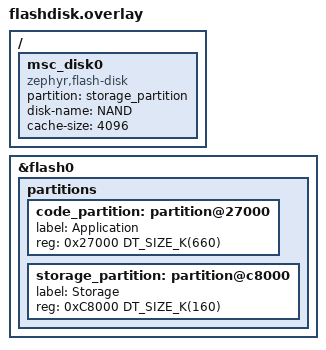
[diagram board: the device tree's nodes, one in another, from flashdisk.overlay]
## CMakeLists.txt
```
# SPDX-License-Identifier: Apache-2.0

cmake_minimum_required(VERSION 3.20.0)
find_package(Zephyr REQUIRED HINTS $ENV{ZEPHYR_BASE})
project(lsm6dsl)

FILE(GLOB app_sources src/*.c)
target_sources(app PRIVATE ${app_sources})

set(MOTION_DIR ${CMAKE_CURRENT_SOURCE_DIR}/../../../examples/motion_recognition/)
set(MOTION_MODEL_IN ${CMAKE_CURRENT_SOURCE_DIR}/combined.estimator.pickle)
set(MOTION_MODEL_OUT ${CMAKE_CURRENT_BINARY_DIR}/motion_model.h)

set(GRAVITY_FILTER_OUT ${CMAKE_CURRENT_BINARY_DIR}/motion_gravity_lowpass.h)

# Custom command for motion_model.h
add_custom_command(
  OUTPUT ${MOTION_MODEL_OUT}
  COMMAND ${CMAKE_COMMAND} -E make_directory ${CMAKE_CURRENT_BINARY_DIR}
  COMMAND python3 ${MOTION_DIR}/tools/convert_model.py --out ${MOTION_MODEL_OUT} --model ${MOTION_MODEL_IN}
  DEPENDS ${MOTION_DIR}/tools/convert_model.py
  COMMENT "Generating motion_model.h"
  WORKING_DIRECTORY ${CMAKE_CURRENT_SOURCE_DIR}
)
add_custom_target(generate_model ALL
  DEPENDS ${MOTION_MODEL_IN} ${MOTION_MODEL_OUT}
)

# Custom command for gravity filter
add_custom_command(
  OUTPUT ${GRAVITY_FILTER_OUT}
  COMMAND ${CMAKE_COMMAND} -E make_directory ${CMAKE_CURRENT_BINARY_DIR}
  COMMAND python3 ${MOTION_DIR}/tools/gravity_lowpass.py --out ${GRAVITY_FILTER_OUT} --format header
  DEPENDS ${MOTION_DIR}/tools/gravity_lowpass.py
  COMMENT "Generating gravity_lowpass.h"
  WORKING_DIRECTORY ${CMAKE_CURRENT_SOURCE_DIR}
)
add_custom_target(generate_filter ALL
  DEPENDS ${GRAVITY_FILTER_OUT}
)

target_include_directories(app PRIVATE 
    ${MOTION_DIR}
    ${CMAKE_CURRENT_BINARY_DIR}
    ${ZEPHYR_BASE}/samples/subsys/usb/common
)

add_dependencies(app generate_model generate_filter)

target_sources(app PRIVATE
    # ${ZEPHYR_BASE}/samples/subsys/usb/common/sample_usbd_init.c
)
```

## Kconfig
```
# Copyright (c) 2019-2020 Nordic Semiconductor ASA
# SPDX-License-Identifier: Apache-2.0

menu "MSC sample options"

config APP_WIPE_STORAGE
	bool "Option to clear the flash area before mounting"
	help
	  Use this to force an existing file system to be created.

choice
	prompt "Storage and file system type used by the application"
	default APP_MSC_STORAGE_NONE
	help
	  Specify the type of storage and file system.

config APP_MSC_STORAGE_NONE
	bool "Use RAM disk as block device"

config APP_MSC_STORAGE_RAM
	bool "Use RAM disk and FAT file system"
	imply FILE_SYSTEM
	imply FAT_FILESYSTEM_ELM

config APP_MSC_STORAGE_FLASH_FATFS
	bool "Use FLASH disk and FAT file system"
	imply DISK_DRIVER_FLASH
	imply FILE_SYSTEM
	imply FAT_FILESYSTEM_ELM

config APP_MSC_STORAGE_FLASH_LITTLEFS
	bool "Use FLASH disk and LittleFS"
	imply DISK_DRIVER_FLASH
	imply FILE_SYSTEM
	imply FILE_SYSTEM_LITTLEFS

config APP_MSC_STORAGE_SDCARD
	bool "Use SDHC and FAT file system"
	imply DISK_DRIVER_SDMMC
	imply FILE_SYSTEM
	imply FAT_FILESYSTEM_ELM

endchoice

config MASS_STORAGE_DISK_NAME
	default "NAND" if DISK_DRIVER_FLASH
	default "RAM" if DISK_DRIVER_RAM
	default "SD" if DISK_DRIVER_SDMMC

if DISK_DRIVER_FLASH

config FLASH_MAP
	default y

config FLASH_PAGE_LAYOUT
	default y

config FLASH_LOG_LEVEL
	default 3

if NORDIC_QSPI_NOR

config NORDIC_QSPI_NOR_FLASH_LAYOUT_PAGE_SIZE
	default 4096

endif # NORDIC_QSPI_NOR

endif # DISK_DRIVER_FLASH

endmenu


menu "USB sample options"
	depends on USB_DEVICE_STACK_NEXT

config SAMPLE_USBD_MANUFACTURER
	string "USB device sample manufacturer string"
	default "Zephyr Project"
	help
	  USB device sample manufacturer string.

config SAMPLE_USBD_PRODUCT
	string "USB device sample product string"
	default "USBD sample"
	help
	  USB device sample product stringa.

config SAMPLE_USBD_PID
	hex "USB device sample Product ID"
	default 0x0001
	help
	  USB device sample Product ID.

config SAMPLE_USBD_SELF_POWERED
	bool "USB device sample Self-powered attribute"
	default y
	help
	  Set the Self-powered attribute in the sample configuration.

config SAMPLE_USBD_REMOTE_WAKEUP
	bool "USB device sample Remote Wakeup attribute"
	help
	  Set the Remote Wakeup attribute in the sample configuration.

config SAMPLE_USBD_MAX_POWER
	int "USB device sample bMaxPower value"
	default 125
	range 0 250
	help
	  bMaxPower value in the sample configuration in 2 mA units.

config SAMPLE_USBD_20_EXTENSION_DESC
	bool "Use default USB 2.0 Extension Descriptor"
	depends on USBD_BOS_SUPPORT
	help
	  Set bcdUSB value to 0201 and use default USB 2.0 Extension Descriptor.

endmenu


source "Kconfig.zephyr"
```

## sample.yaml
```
sample:
  name: Reading sensors with queue
tests:
  sample.sensor.lsm6dsl:
    harness: console
    tags: sensors
    depends_on: lsm6dsl
    timeout: 15
    harness_config:
      type: multi_line
      ordered: true
      regex:
        - "accel x:[-.0-9]* ms/2 y:[-.0-9]* ms/2 z:[-.0-9]* ms/2"
        - "gyro x:[-.0-9]* dps y:[-.0-9]* dps z:[-.0-9]* dps"
        - "loop:[0-9]* trig_cnt:[0-9]*"
```

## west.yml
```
# Copyright (c) 2021 Nordic Semiconductor ASA
# SPDX-License-Identifier: Apache-2.0

manifest:
  remotes:
    - name: zephyrproject-rtos
      url-base: https://github.com/zephyrproject-rtos

  projects:
    - name: zephyr
      remote: zephyrproject-rtos
      revision: v4.2.1
      import:
        # By using name-allowlist we can clone only the modules that are strictly needed
        name-allowlist:
          - cmsis_6      # required by the ARM port
          - hal_nordic # required by the qemu cortex board (Nordic based)

    - name: fatfs
      url: https://github.com/zephyrproject-rtos/fatfs
      revision: 16245c7c41d2b79e74984f49b5202551786b8a9b
      path: modules/fs/fatfs

    - name: emlearn
      url: https://github.com/emlearn/emlearn
      revision: master
```

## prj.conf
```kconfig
CONFIG_STDOUT_CONSOLE=y

#USB related configs
CONFIG_USB_DEVICE_STACK=y
CONFIG_USB_DEVICE_PRODUCT="Zephyr MSC sample"
CONFIG_USB_DEVICE_PID=0x0008
CONFIG_LOG=y
CONFIG_USB_DRIVER_LOG_LEVEL_ERR=y
CONFIG_USB_MASS_STORAGE=y
CONFIG_USB_DEVICE_LOG_LEVEL_ERR=y
CONFIG_USB_MASS_STORAGE_LOG_LEVEL_ERR=y
CONFIG_USB_DEVICE_INITIALIZE_AT_BOOT=n
CONFIG_FILE_SYSTEM_MKFS=y

CONFIG_MAIN_STACK_SIZE=1536

CONFIG_FILE_SYSTEM=y
CONFIG_POSIX_API=y
CONFIG_NEWLIB_LIBC=y

# enable the emlearn module
CONFIG_EMLEARN=y

# enable LSM6 accel
CONFIG_I2C=y
CONFIG_SENSOR=y
```

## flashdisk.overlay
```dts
/*
 * Copyright The Zephyr Project Contributors
 *
 * SPDX-License-Identifier: Apache-2.0
 */


/delete-node/ &code_partition;
/delete-node/ &storage_partition;

&flash0 {
    partitions {
        code_partition: partition@27000 {
            label = "Application";
            reg = <0x27000 DT_SIZE_K(660)>;  /* Reduce app to 660KB */
        };

        storage_partition: partition@c8000 {
            label = "Storage";
            reg = <0xC8000 DT_SIZE_K(160)>;  /* Increase storage to 160KB */
        };
    };
};


/ {
	msc_disk0 {
		compatible = "zephyr,flash-disk";
		partition = <&storage_partition>;
		disk-name = "NAND";
		cache-size = <4096>;
	};
};
```

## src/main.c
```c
/*
 * Copyright (c) 2018 STMicroelectronics
 *
 * SPDX-License-Identifier: Apache-2.0
 */

#include <zephyr/kernel.h>
#include <zephyr/device.h>
#include <zephyr/drivers/sensor.h>
#include <zephyr/logging/log.h>
#include <zephyr/sys/util.h>
#include <zephyr/fs/fs.h>
#include <zephyr/storage/disk_access.h>

#include <stdio.h>
#include <ctype.h>

#include <eml_csv.h>
#include <eml_fileio.h>


#include "sample_usbd.h"

int usb_disk_setup(void);

// Application includes
#include "sensor_reader.h"
#include "motion_preprocessing.h"
#include "motion_gravity_lowpass.h"

LOG_MODULE_REGISTER(main, LOG_LEVEL_INF);

// Configuration
#define SAMPLERATE 52
#define WINDOW_LENGTH 50
// TODO: support hop_length < window_length (overlap)
#define HOP_LENGTH 50

#define N_CHANNELS 6
enum sensor_channel sensor_reader_channels[N_CHANNELS] = {
	SENSOR_CHAN_ACCEL_X,
	SENSOR_CHAN_ACCEL_Y,
	SENSOR_CHAN_ACCEL_Z,
	SENSOR_CHAN_GYRO_X,
	SENSOR_CHAN_GYRO_Y,
	SENSOR_CHAN_GYRO_Z,
};
const char *channel_names[N_CHANNELS] = {
    "accel_x",
    "accel_y",
    "accel_z",
    "gyro_x",
    "gyro_y",
    "gyro_z"
};

// FIXME: load model
#define MOTION_MODEL_CLASSES 0
#define FEATURE_COLUMNS_LENGTH (1+motion_features_length+1+MOTION_MODEL_CLASSES+MOTION_FFT_LENGTH)
float feature_values[FEATURE_COLUMNS_LENGTH];


// Reader internals
float sensor_reader_output_buffer[WINDOW_LENGTH*N_CHANNELS];
float sensor_reader_new_buffer[HOP_LENGTH*N_CHANNELS];

#define SENSOR_READER_STACK_SIZE 1000
K_THREAD_STACK_DEFINE(sensor_reader_stack, SENSOR_READER_STACK_SIZE);
struct k_thread sensor_reader_thread;

K_MSGQ_DEFINE(sensor_reader_queue, sizeof(struct sensor_chunk_msg), 1, 1);

// Storing code


int write_header(const char *output_path)
{
    EmlCsvWriter _writer = {
        .n_columns = N_CHANNELS,
        .write = eml_fileio_write,
        .stream = NULL, // initialized later
    };
    EmlCsvWriter *writer = &_writer;

    // Setup file output
    FILE *write_file = fopen(output_path, "w");
    if (write_file == NULL) {
        fprintf(stderr, "failed to open output path=%s\n", output_path);
        return -1;
    }
    writer->stream = write_file;

    // Write output header
    const EmlError write_header_err = \
        eml_csv_writer_write_header(writer, channel_names, N_CHANNELS);
    if (write_header_err != EmlOk) {
        fprintf(stderr, "header-write-fail error=%d \n", write_header_err);
        fclose(writer->stream);
        return -1;
    }

    fclose(writer->stream);
    return 0;
}

int write_samples(const char *output_path, float *values, int length)
{
    // Open file in append mode, write data and close file
    // Without fclose() the data does not get to syncronized to disk
    EmlCsvWriter _writer = {
        .n_columns = N_CHANNELS,
        .write = eml_fileio_write,
        .stream = NULL, // initialized later
    };
    EmlCsvWriter *writer = &_writer;

    // Setup file output
    FILE *write_file = fopen(output_path, "a");
    if (write_file == NULL) {
        fprintf(stderr, "failed to open output\n");
        return -1;
    }
    writer->stream = write_file;

    // Write sensor data values to file
    const int rows = length / N_CHANNELS;
    int write_errors = 0;
    int write_success = 0;
    for (int i=0; i<rows; i++) {
        const float *row = values + (i*N_CHANNELS);
        const EmlError write_err = \
            eml_csv_writer_write_data(writer, row, N_CHANNELS);
        if (write_err != EmlOk) {
            write_errors += 1;
        } else {
            write_success += 1;
        }
    }

    fclose(writer->stream);

    if (write_errors) {
        return -2;
    } else if (write_success == 0) {
        return -3;
    }

    return 0; 
}


int
setup_sensor(const struct device *const lsm6dsl_dev)
{
	struct sensor_value odr_attr;
	if (!device_is_ready(lsm6dsl_dev)) {
		printk("sensor: device not ready.\n");
		return -1;
	}

	/* set accel/gyro sampling frequency */
	odr_attr.val1 = SAMPLERATE;
	odr_attr.val2 = 0;

	if (sensor_attr_set(lsm6dsl_dev, SENSOR_CHAN_ACCEL_XYZ,
			    SENSOR_ATTR_SAMPLING_FREQUENCY, &odr_attr) < 0) {
		printk("Cannot set sampling frequency for accelerometer.\n");
		return -2;
	}

	if (sensor_attr_set(lsm6dsl_dev, SENSOR_CHAN_GYRO_XYZ,
			    SENSOR_ATTR_SAMPLING_FREQUENCY, &odr_attr) < 0) {
		printk("Cannot set sampling frequency for gyro.\n");
		return -3;
	}

    return 0;
}

int read_file(const char* filename, char* buffer, size_t buffer_size) {
    FILE* file = fopen(filename, "r");
    if (file == NULL) {
        fprintf(stderr, "read_file: Failed to open file %s\n", filename);
        return -1;
    }

    // Read up to buffer_size - 1 characters
    size_t bytes_read = fread(buffer, 1, buffer_size - 1, file);

    // Check if file is larger than buffer
    if (!feof(file)) {
        fprintf(stderr, "Error: File too large for buffer\n");
        fclose(file);
        return -1;
    }

    buffer[bytes_read] = '\0';
    fclose(file);

    // Strip trailing whitespace
    while (bytes_read > 0 && isspace((unsigned char)buffer[bytes_read - 1])) {
        buffer[--bytes_read] = '\0';
    }

    return bytes_read;
}


// Large, use global and not stack
struct motion_preprocessor _preprocessor;

int main(void) {

    // Setup USB disk
    const int usb_err = usb_disk_setup();
    if (usb_err) {
		LOG_ERR("Failed to setup USB disk");
    } else {
		LOG_ERR("Now in USB mass storage mode");
    }

    const char *save_directory = "/NAND:";

    // See if we should record or not
    // Read the filename to write from a file 
    char recording_name[40] = {0};
    const char *record_name_path = "/NAND:/record.txt";
    const int record_read = read_file(record_name_path, recording_name, 40);
    const bool recording_enabled = record_read > 0;
 
    char recording_save_path[100] = {0};
    if (recording_enabled) {
        const int path_written = snprintf(recording_save_path, 100, "%s/%s.csv",
                save_directory, recording_name);
        if (path_written < 0 || path_written == 100) {
            return 2;
        }
        const int header_err = write_header(recording_save_path);
        if (header_err) {
            return 3;
        }
    }

    printk("record-check enabled=%d path=%s \n",
        (int)recording_enabled, recording_save_path);


    // Setup sensor reading
    struct sensor_chunk_msg chunk;

	const struct device *const lsm6dsl_dev = DEVICE_DT_GET_ONE(st_lsm6dsl);

    struct sensor_chunk_reader reader = {
        .samplerate = SAMPLERATE,
        .window_length = WINDOW_LENGTH,
        .hop_length = HOP_LENGTH,
        .thread = &sensor_reader_thread,
        .thread_priority = 10,
        .read_samples = sensor_reader_new_buffer,
        .read_samples_index = 0,
        .output_buffer = sensor_reader_output_buffer,
        .output_buffer_index = 0,
        .n_channels = N_CHANNELS,
        .channels = sensor_reader_channels,
        .dev = lsm6dsl_dev,
        .queue = &sensor_reader_queue,
        .stack = sensor_reader_stack,
        .stack_size = SENSOR_READER_STACK_SIZE,
        .fetch_errors = 0,
        .get_errors = 0,
        .put_errors = 0
    };

    // Setup data preprocessing
    struct motion_preprocessor *preprocessor = &_preprocessor;

    const int init_err = motion_preprocessor_init(preprocessor, SAMPLERATE, WINDOW_LENGTH);
    if (init_err != 0) {
        fprintf(stderr, "preprocess init error %d\n", init_err);
        return -2;
    }

#if 1
    const int gravity_err = motion_preprocessor_set_gravity_lowpass(preprocessor,
        gravity_lowpass_values, gravity_lowpass_length);
    if (gravity_err != 0) {
        fprintf(stderr, "lowpass config error %d\n", gravity_err);
        return 2;
    }
#endif

    const int fft_config_err = \
        motion_preprocessor_set_fft_features(preprocessor, 1, 10);
    if (fft_config_err != 0) {
        fprintf(stderr, "FFT config error %d\n", fft_config_err);
        return 2;
    }

    if (!device_is_ready(lsm6dsl_dev)) {
        printk("sensor: device %s not ready.\n", lsm6dsl_dev->name);
        return 0;
    }

    // Setup sensor
    setup_sensor(lsm6dsl_dev);

    const int n_features = motion_preprocessor_get_feature_length(preprocessor);
    if (n_features < 0) {
        return 2;
    }

    // Start high-priority thread for collecting data
    sensor_chunk_reader_start(&reader);

    int iteration = 0;
    float previous_input = 0.0f;
    while (1) {
        const float uptime = k_uptime_get() / 1000.0;

        // check for new data
        const int get_error = k_msgq_get(reader.queue, &chunk, K_NO_WAIT);
        if (get_error == 0) {

            const float dt = uptime - previous_input;

            int write_err = 0;

            if (recording_enabled) {
                write_err = write_samples(recording_save_path, chunk.buffer, chunk.length);
            }

            //printk("process-chunk length=%d \n", chunk.length);
            const int run_status = \
                motion_preprocessor_run(preprocessor, chunk.buffer, chunk.length);

            // Log extracted features
            const int copy_err = \
                motion_preprocessor_get_features(preprocessor, feature_values, FEATURE_COLUMNS_LENGTH);

            printk("features run_err=%d copy_err=%d write_err=%d | ",
                run_status, copy_err, write_err);

            printk("l=%d dt=%.3f time=%.3f", 
                chunk.length, (double)dt, (double)uptime
            );
#if 0
            for (int i=0; i<n_features; i++) {
                printk("%.4f ", (double)feature_values[i]);
            }
#endif
            printk("\n");

            // TODO: run through ML model, print outputs
            previous_input = uptime;
        }

        iteration += 1;
	    k_msleep(100);
    }

    return 0;
}
```

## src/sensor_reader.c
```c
#include <zephyr/kernel.h>
#include <zephyr/device.h>
#include <zephyr/drivers/sensor.h>

#include "sensor_reader.h"


// Designed to be called in a new thread
static void
sensor_chunk_reader_task(void *context, void *, void *)
{
    struct sensor_chunk_reader * self = (struct sensor_chunk_reader *)context;
    float values[SENSOR_CHUNK_READER_MAX_CHANNELS];

    // MAYBE: support a way of exiting loop gracefully?
    while (1) {

        // Read data
	    const int fetch_ret = sensor_sample_fetch(self->dev);
	    if (fetch_ret < 0) {
            self->fetch_errors += 0;

	    }
	    for (size_t i = 0; i < self->n_channels; i++) {
            struct sensor_value value;
		    const int get_ret = sensor_channel_get(self->dev, self->channels[i], &value);
            values[i] = sensor_value_to_double(&value);

		    if (get_ret < 0) {
                self->get_errors += 1;
		    }
	    }

        // Buffer received data
        const int read_offset = (self->read_samples_index*self->n_channels);
        memcpy(self->read_samples+read_offset, values, sizeof(float)*self->n_channels);
        self->read_samples_index += 1;

#if 0
        printk("reader-task-got-data index=%d \n", self->read_samples_index);
#endif

        // TODO: respect hop_length, using overlap
        if (self->read_samples_index == self->window_length) {
            const int out_length = self->n_channels * self->window_length;

            // Push onto output buffer
            memcpy(self->output_buffer, self->read_samples, sizeof(float)*out_length);
            self->read_samples_index = 0;

            // Send as message
            struct sensor_chunk_msg msg = { 1, self->output_buffer, out_length };
#if 0
    printk("reader-task-got-data index=%d \n", self->read_samples_index);
#endif
            const int put_status = k_msgq_put(self->queue, &msg, K_NO_WAIT);
            if (put_status < 0) {
                self->put_errors += 1;
            }

        }

        const int wait_timeout_us = 1000000/self->samplerate;
        k_usleep(wait_timeout_us);
    }
}


void
sensor_chunk_reader_start(struct sensor_chunk_reader *self) 
{
    // start new thread
    k_tid_t thread_id = k_thread_create(self->thread, self->stack,
                                     self->stack_size,
                                     sensor_chunk_reader_task,
                                     self, NULL, NULL,
                                     self->thread_priority, 0, K_NO_WAIT);

    self->thread_id = thread_id;
}


void
sensor_chunk_reader_stop(struct sensor_chunk_reader *self) 
{
    // FIXME: should probably do something more graceful
    k_thread_abort(self->thread_id);
}
```

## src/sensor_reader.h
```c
#ifndef SENSOR_CHUNK_READER_MAX_CHANNELS
#define SENSOR_CHUNK_READER_MAX_CHANNELS 9
#endif

struct sensor_chunk_reader {
    int window_length;
    int hop_length;
    int samplerate;

    float *read_samples;
    int read_samples_index;

    float *output_buffer;
    int output_buffer_index;

    int n_channels;
    enum sensor_channel *channels;

    const struct device *dev;
    struct k_msgq *queue;
    struct k_thread *thread;
    int thread_priority;
    k_tid_t thread_id;
    k_thread_stack_t *stack;
    size_t stack_size;

    int fetch_errors;
    int get_errors;
    int put_errors;
};

struct sensor_chunk_msg {
    int sample_no;
    float *buffer; // n_channels * window_length
    size_t length;
};

void sensor_chunk_reader_start(struct sensor_chunk_reader *self);
void sensor_chunk_reader_stop(struct sensor_chunk_reader *self);
```

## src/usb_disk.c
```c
// Based on samples/subsys/usb/mass/src/main.c

#include <zephyr/kernel.h>
#include <zephyr/logging/log.h>
#include <zephyr/usb/usb_device.h>
#include <zephyr/usb/usbd.h>
#include <zephyr/usb/class/usbd_msc.h>
#include <zephyr/fs/fs.h>
#include <stdio.h>

LOG_MODULE_REGISTER(usb_disk, LOG_LEVEL_INF);

#if CONFIG_DISK_DRIVER_FLASH
#include <zephyr/storage/flash_map.h>
#endif

#if CONFIG_FAT_FILESYSTEM_ELM
#include <ff.h>
#endif

#if CONFIG_FILE_SYSTEM_LITTLEFS
#include <zephyr/fs/littlefs.h>
FS_LITTLEFS_DECLARE_DEFAULT_CONFIG(storage);
#endif

#if !defined(CONFIG_DISK_DRIVER_FLASH) && \
	!defined(CONFIG_DISK_DRIVER_RAM) && \
	!defined(CONFIG_DISK_DRIVER_SDMMC)
#error No supported disk driver enabled
#endif

#define STORAGE_PARTITION		storage_partition
#define STORAGE_PARTITION_ID		FIXED_PARTITION_ID(STORAGE_PARTITION)

static struct fs_mount_t fs_mnt;

#if defined(CONFIG_USB_DEVICE_STACK_NEXT)
static struct usbd_context *sample_usbd;

#if CONFIG_DISK_DRIVER_RAM
USBD_DEFINE_MSC_LUN(ram, "RAM", "Zephyr", "RAMDisk", "0.00");
#endif

#if CONFIG_DISK_DRIVER_FLASH
USBD_DEFINE_MSC_LUN(nand, "NAND", "Zephyr", "FlashDisk", "0.00");
#endif

#if CONFIG_DISK_DRIVER_SDMMC
USBD_DEFINE_MSC_LUN(sd, "SD", "Zephyr", "SD", "0.00");
#endif

static int enable_usb_device_next(void)
{
	int err;

	sample_usbd = sample_usbd_init_device(NULL);
	if (sample_usbd == NULL) {
		LOG_ERR("Failed to initialize USB device");
		return -ENODEV;
	}

	err = usbd_enable(sample_usbd);
	if (err) {
		LOG_ERR("Failed to enable device support");
		return err;
	}

	LOG_DBG("USB device support enabled");

	return 0;
}
#endif /* defined(CONFIG_USB_DEVICE_STACK_NEXT) */

static int setup_flash(struct fs_mount_t *mnt)
{
	int rc = 0;
#if CONFIG_DISK_DRIVER_FLASH
	unsigned int id;
	const struct flash_area *pfa;

	mnt->storage_dev = (void *)STORAGE_PARTITION_ID;
	id = STORAGE_PARTITION_ID;

	rc = flash_area_open(id, &pfa);
	printk("Area %u at 0x%x on %s for %u bytes\n",
	       id, (unsigned int)pfa->fa_off, pfa->fa_dev->name,
	       (unsigned int)pfa->fa_size);

	if (rc < 0 && IS_ENABLED(CONFIG_APP_WIPE_STORAGE)) {
		printk("Erasing flash area ... ");
		rc = flash_area_flatten(pfa, 0, pfa->fa_size);
		printk("%d\n", rc);
	}

	if (rc < 0) {
		flash_area_close(pfa);
	}
#endif
	return rc;
}

static int mount_app_fs(struct fs_mount_t *mnt)
{
	int rc;

#if CONFIG_FAT_FILESYSTEM_ELM
	static FATFS fat_fs;

	mnt->type = FS_FATFS;
	mnt->fs_data = &fat_fs;
	if (IS_ENABLED(CONFIG_DISK_DRIVER_RAM)) {
		mnt->mnt_point = "/RAM:";
	} else if (IS_ENABLED(CONFIG_DISK_DRIVER_SDMMC)) {
		mnt->mnt_point = "/SD:";
	} else {
		mnt->mnt_point = "/NAND:";
	}

#elif CONFIG_FILE_SYSTEM_LITTLEFS
	mnt->type = FS_LITTLEFS;
	mnt->mnt_point = "/lfs";
	mnt->fs_data = &storage;
#endif
	rc = fs_mount(mnt);

	return rc;
}

static void setup_disk(void)
{
	struct fs_mount_t *mp = &fs_mnt;
	struct fs_dir_t dir;
	struct fs_statvfs sbuf;
	int rc;

	fs_dir_t_init(&dir);

	if (IS_ENABLED(CONFIG_DISK_DRIVER_FLASH)) {
		rc = setup_flash(mp);
		if (rc < 0) {
			LOG_ERR("Failed to setup flash area");
			return;
		}
	}

	if (!IS_ENABLED(CONFIG_FILE_SYSTEM_LITTLEFS) &&
	    !IS_ENABLED(CONFIG_FAT_FILESYSTEM_ELM)) {
		LOG_INF("No file system selected");
		return;
	}

	rc = mount_app_fs(mp);
	if (rc < 0) {
		LOG_ERR("Failed to mount filesystem");
		return;
	}

	/* Allow log messages to flush to avoid interleaved output */
	k_sleep(K_MSEC(50));

	printk("Mount %s: %d\n", fs_mnt.mnt_point, rc);

	rc = fs_statvfs(mp->mnt_point, &sbuf);
	if (rc < 0) {
		printk("FAIL: statvfs: %d\n", rc);
		return;
	}

	printk("%s: bsize = %lu ; frsize = %lu ;"
	       " blocks = %lu ; bfree = %lu\n",
	       mp->mnt_point,
	       sbuf.f_bsize, sbuf.f_frsize,
	       sbuf.f_blocks, sbuf.f_bfree);

	rc = fs_opendir(&dir, mp->mnt_point);
	printk("%s opendir: %d\n", mp->mnt_point, rc);

	if (rc < 0) {
		LOG_ERR("Failed to open directory");
	}

	while (rc >= 0) {
		struct fs_dirent ent = { 0 };

		rc = fs_readdir(&dir, &ent);
		if (rc < 0) {
			LOG_ERR("Failed to read directory entries");
			break;
		}
		if (ent.name[0] == 0) {
			printk("End of files\n");
			break;
		}
		printk("  %c %u %s\n",
		       (ent.type == FS_DIR_ENTRY_FILE) ? 'F' : 'D',
		       ent.size,
		       ent.name);
	}

	(void)fs_closedir(&dir);

	return;
}

int usb_disk_setup(void)
{
	int ret;

    // FIXME: setup_disk() makes device not show up on USB at all
#if 1
	setup_disk();
#else
    return -2;
#endif

#if defined(CONFIG_USB_DEVICE_STACK_NEXT)
	ret = enable_usb_device_next();
#else
	ret = usb_enable(NULL);
#endif
	if (ret != 0) {
		LOG_ERR("Failed to enable USB");
		return 0;
	}

	LOG_INF("The device is put in USB mass storage mode.\n");


	if (ret != 0) {
		LOG_ERR("Failed to enable USB");
		return -1;
	}

	return 0;
}
```
